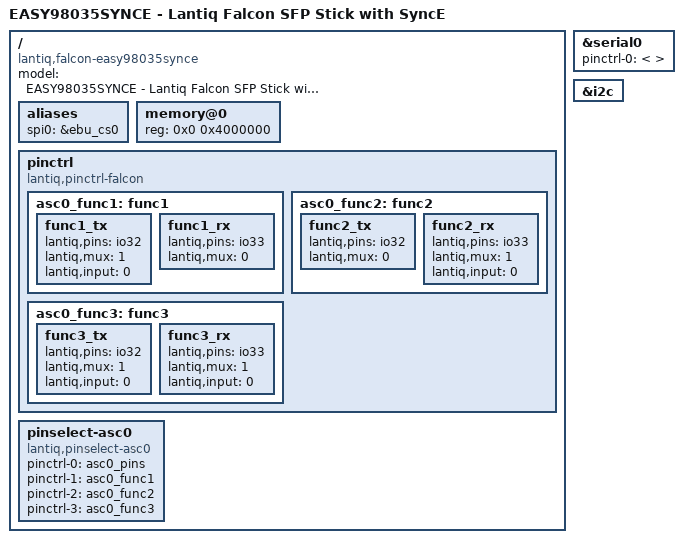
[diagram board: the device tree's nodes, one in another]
/dts-v1/;

#include "falcon.dtsi"
#include "falcon-sflash-16M.dtsi"

/ {
	model = "EASY98035SYNCE - Lantiq Falcon SFP Stick with SyncE";
	compatible = "lantiq,falcon-easy98035synce", "lantiq,falcon-sfp", "lantiq,falcon";

	aliases {
		spi0 = &ebu_cs0;
	};

	memory@0 {
		device_type = "memory";
		reg = <0x0 0x4000000>;  // 64M at 0x0
	};

	pinctrl {
		compatible = "lantiq,pinctrl-falcon";

		asc0_func1: func1 {
			func1_tx {
				lantiq,pins = "io32";
				lantiq,mux = <1>;
				lantiq,input = <0>;
			};
			func1_rx {
				lantiq,pins = "io33";
				lantiq,mux = <0>;
			};
		};
		asc0_func2: func2 {
			func2_tx {
				lantiq,pins = "io32";
				lantiq,mux = <0>;
			};
			func2_rx {
				lantiq,pins = "io33";
				lantiq,mux = <1>;
				lantiq,input = <0>;
			};
		};
		asc0_func3: func3 {
			func3_tx {
				lantiq,pins = "io32";
				lantiq,mux = <1>;
				lantiq,input = <0>;
			};
			func3_rx {
				lantiq,pins = "io33";
				lantiq,mux = <1>;
				lantiq,input = <0>;
			};
		};
	};

	pinselect-asc0 {
		compatible = "lantiq,pinselect-asc0";
		pinctrl-names = "asc0", "func1", "func2", "func3";
		pinctrl-0 = <&asc0_pins>;
		pinctrl-1 = <&asc0_func1>;
		pinctrl-2 = <&asc0_func2>;
		pinctrl-3 = <&asc0_func3>;
	};
};

&serial0 {
	pinctrl-names = "default";
	/* use "empty" pinctrl to leave setting from u-boot enabled */
	pinctrl-0 = < >;
};

&i2c {
	status = "okay";
};
